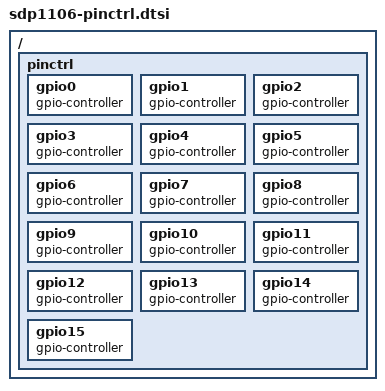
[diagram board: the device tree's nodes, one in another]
/*
 * Copyright (C) 2013 Samsung Electronics Co.Ltd
 *
 * This program is free software; you can redistribute it and/or modify
 * it under the terms of the GNU General Public License version 2 as
 * published by the Free Software Foundation.
 */

/ {
	pinctrl{
		gpio0: gpio0 {
			gpio-controller;
			#gpio-cells = <2>;
		};

		gpio1: gpio1 {
			gpio-controller;
			#gpio-cells = <2>;
		};

		gpio2: gpio2 {
			gpio-controller;
			#gpio-cells = <2>;
		};

		gpio3: gpio3 {
			gpio-controller;
			#gpio-cells = <2>;
		};

		gpio4: gpio4 {
			gpio-controller;
			#gpio-cells = <2>;
		};

		gpio5: gpio5 {
			gpio-controller;
			#gpio-cells = <2>;
		};

		gpio6: gpio6 {
			gpio-controller;
			#gpio-cells = <2>;
		};

		gpio7: gpio7 {
			gpio-controller;
			#gpio-cells = <2>;
		};

		gpio8: gpio8 {
			gpio-controller;
			#gpio-cells = <2>;
		};

		gpio9: gpio9 {
			gpio-controller;
			#gpio-cells = <2>;
		};

		gpio10: gpio10 {
			gpio-controller;
			#gpio-cells = <2>;
		};

		gpio11: gpio11 {
			gpio-controller;
			#gpio-cells = <2>;
		};

		gpio12: gpio12 {
			gpio-controller;
			#gpio-cells = <2>;
		};

		gpio13: gpio13 {
			gpio-controller;
			#gpio-cells = <2>;
		};

		gpio14: gpio14 {
			gpio-controller;
			#gpio-cells = <2>;
		};

		gpio15: gpio15 {
			gpio-controller;
			#gpio-cells = <2>;
		};
	};
};

